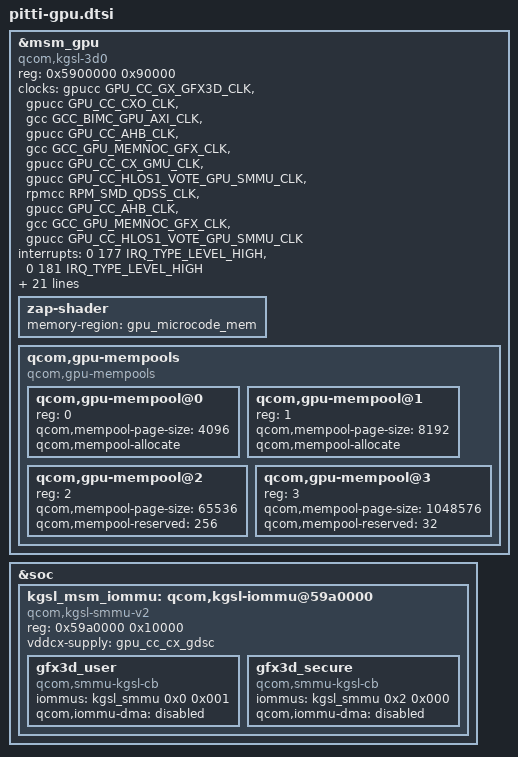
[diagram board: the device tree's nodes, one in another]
#define MHZ_TO_KBPS(mhz, w) ((mhz * 1000000 * w) / (1024))

&msm_gpu {
	compatible = "qcom,kgsl-3d0", "qcom,adreno-gpu-a611";
	status = "ok";

	reg = <0x5900000 0x90000>;

	reg-names = "kgsl_3d0_reg_memory";

	clocks = <&gpucc GPU_CC_GX_GFX3D_CLK>,
		<&gpucc GPU_CC_CXO_CLK>,
		<&gcc GCC_BIMC_GPU_AXI_CLK>,
		<&gpucc GPU_CC_AHB_CLK>,
		<&gcc GCC_GPU_MEMNOC_GFX_CLK>,
		<&gpucc GPU_CC_CX_GMU_CLK>,
		<&gpucc GPU_CC_HLOS1_VOTE_GPU_SMMU_CLK>,
		<&rpmcc RPM_SMD_QDSS_CLK>,
		<&gpucc GPU_CC_AHB_CLK>,
		<&gcc GCC_GPU_MEMNOC_GFX_CLK>,
		<&gpucc GPU_CC_HLOS1_VOTE_GPU_SMMU_CLK>;

	clock-names = "core_clk",
		"rbbmtimer_clk",
		"iface_clk",
		"ahb_clk",
		"mem_clk",
		"gmu_clk",
		"smmu_vote",
		"apb_pclk",
		"gpu_cc_ahb",
		"gcc_gpu_memnoc_gfx",
		"gpu_cc_hlos1_vote_gpu_smmu";

	interrupts = <0 177 IRQ_TYPE_LEVEL_HIGH>, <0 181 IRQ_TYPE_LEVEL_HIGH>;
	interrupt-names = "kgsl_3d0_irq", "freq_limiter_irq";

	resets = <&gpucc GPU_CC_FREQUENCY_LIMITER_IRQ_CLEAR>;
	reset-names = "freq_limiter_irq_clear";

	qcom,chipid = <0x06010100>;
	qcom,gpu-model = "Adreno611v1";

	regulator-names = "vddcx", "vdd";
	vddcx-supply = <&gpu_cc_cx_gdsc>;
	vdd-supply = <&gpu_cc_gx_gdsc>;

	qcom,min-access-length = <32>;

	qcom,ubwc-mode = <2>;

	qcom,enable-ca-jump;

	qcom,tzone-names = "gpuss";

	/* Context aware jump busy penalty in us */
	qcom,ca-busy-penalty = <12000>;

	nvmem-cells = <&gpu_speed_bin>;
	nvmem-cell-names = "speed_bin";

	interconnects = <&bimc MASTER_GRAPHICS_3D &bimc SLAVE_EBI_CH0>;
	interconnect-names = "gpu_icc_path";

	qcom,bus-table-ddr =
			<MHZ_TO_KBPS(0, 4)>,    /* index=0  */
			<MHZ_TO_KBPS(200, 4)>,  /* index=1 (LOW SVS) */
			<MHZ_TO_KBPS(547, 4)>,  /* index=2 (LOW SVS) */
			<MHZ_TO_KBPS(768, 4)>,  /* index=3 (SVS) */
			<MHZ_TO_KBPS(1017, 4)>, /* index=4 (SVS) */
			<MHZ_TO_KBPS(1353, 4)>, /* index=5 (NOM) */
			<MHZ_TO_KBPS(1555, 4)>, /* index=6 (NOM) */
			<MHZ_TO_KBPS(1804, 4)>, /* index=7 (TURBO) */
			<MHZ_TO_KBPS(2092, 4)>; /* index=8 (TURBO_L1) */

	zap-shader {
		memory-region = <&gpu_microcode_mem>;
	};

	qcom,gpu-mempools {
		#address-cells = <1>;
		#size-cells = <0>;
		compatible = "qcom,gpu-mempools";

		/* 4K Page Pool configuration */
		qcom,gpu-mempool@0 {
			reg = <0>;
			qcom,mempool-page-size = <4096>;
			qcom,mempool-allocate;
		};
		/* 8K Page Pool configuration */
		qcom,gpu-mempool@1 {
			reg = <1>;
			qcom,mempool-page-size = <8192>;
			qcom,mempool-allocate;
		};
		/* 64K Page Pool configuration */
		qcom,gpu-mempool@2 {
			reg = <2>;
			qcom,mempool-page-size = <65536>;
			qcom,mempool-reserved = <256>;
		};
		/* 1M Page Pool configuration */
		qcom,gpu-mempool@3 {
			reg = <3>;
			qcom,mempool-page-size = <1048576>;
			qcom,mempool-reserved = <32>;
		};
	};
};

&soc {
	kgsl_msm_iommu: qcom,kgsl-iommu@59a0000 {
		compatible = "qcom,kgsl-smmu-v2";

		reg = <0x59a0000 0x10000>;

		vddcx-supply = <&gpu_cc_cx_gdsc>;

		gfx3d_user: gfx3d_user {
			compatible = "qcom,smmu-kgsl-cb";
			iommus = <&kgsl_smmu 0x0 0x001>;
			qcom,iommu-dma = "disabled";
		};

		gfx3d_secure: gfx3d_secure {
			compatible = "qcom,smmu-kgsl-cb";
			iommus = <&kgsl_smmu 0x2 0x000>;
			qcom,iommu-dma = "disabled";
		};
	};
};
